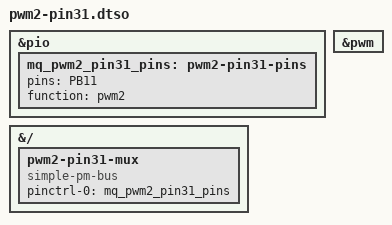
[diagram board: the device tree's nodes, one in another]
// SPDX-License-Identifier: (GPL-2.0+ OR MIT)
// Mangue OS header overlay pwm2-pin31 — GENERATED by tools/gen_overlays.py,
// edit overlays/header_table.py instead.
//
// pin port  role
//  31 PB11  pwm2
// device: /sys/class/pwm/pwmchip0 channel 2

/dts-v1/;
/plugin/;

#include <dt-bindings/gpio/gpio.h>
#include <dt-bindings/interrupt-controller/irq.h>
#include <dt-bindings/input/linux-event-codes.h>

&pio {
	mq_pwm2_pin31_pins: pwm2-pin31-pins {
		pins = "PB11";
		function = "pwm2";
	};
};

&pwm {
	status = "okay";
};

&{/} {
	pwm2-pin31-mux {
		compatible = "simple-pm-bus";
		pinctrl-names = "default";
		pinctrl-0 = <&mq_pwm2_pin31_pins>;
	};
};
